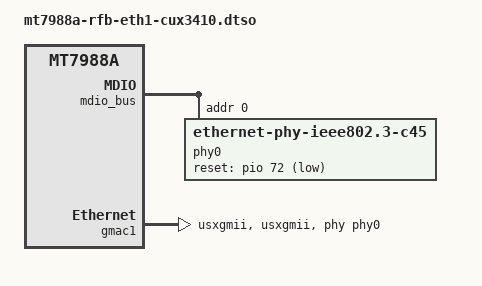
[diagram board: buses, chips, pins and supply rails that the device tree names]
// SPDX-License-Identifier: (GPL-2.0 OR MIT)
/*
 * Copyright (C) 2022 MediaTek Inc.
 * Author: Sam.Shih <sam.shih@mediatek.com>
 */

/dts-v1/;
/plugin/;

#include <dt-bindings/gpio/gpio.h>
#include <dt-bindings/leds/common.h>

/ {
	compatible = "mediatek,mt7988a-rfb", "mediatek,mt7988a";

	fragment@0 {
		target = <&mdio_bus>;
		__overlay__ {
			#address-cells = <1>;
			#size-cells = <0>;

			/* external Aquantia CUX3410 */
			phy0: ethernet-phy@0 {
				reg = <0>;
				compatible = "ethernet-phy-ieee802.3-c45";
				firmware-name = "AQR-G4_v5.7.0-AQR_EVB_Generic_X3410_StdCfg_MDISwap_USX_ID46316_VER2148.cld";
				reset-gpios = <&pio 72 GPIO_ACTIVE_LOW>;
				reset-assert-us = <100000>;
				reset-deassert-us = <221000>;

				leds {
					#address-cells = <1>;
					#size-cells = <0>;

					phy0_led0: aqr_phy0_led0@0 {
						reg = <0>;
						linux,default-trigger = "netdev";
						status = "okay";
					};

					phy0_led1: aqr_phy0_led1@1 {
						reg = <1>;
						linux,default-trigger = "netdev";
						status = "okay";
					};

					phy0_led2: aqr_phy0_led2@2 {
						reg = <2>;
						linux,default-trigger = "netdev";
						status = "okay";
					};
				};
			};
		};
	};

	fragment@1 {
		target = <&gmac1>;
		__overlay__ {
			phy-mode = "usxgmii";
			phy-connection-type = "usxgmii";
			phy = <&phy0>;
			status = "okay";
		};
	};
};
